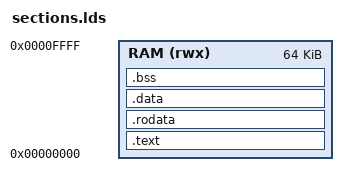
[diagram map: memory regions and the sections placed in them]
/*
 * Linker script for PicoRV32 64KB bare-metal environment
 */
OUTPUT_FORMAT("elf32-littleriscv", "elf32-littleriscv", "elf32-littleriscv")
OUTPUT_ARCH(riscv)
ENTRY(_start)

MEMORY
{
    RAM (rwx) : ORIGIN = 0x00000000, LENGTH = 64K
}

SECTIONS
{
    .text :
    {
        . = ALIGN(4);
        *(.text.entry)
        *(.text)
        *(.text.*)
        . = ALIGN(4);
        _etext = .;
    } > RAM

    .rodata :
    {
        . = ALIGN(4);
        *(.rodata)
        *(.rodata.*)
        *(.srodata)
        *(.srodata.*)
        . = ALIGN(4);
    } > RAM

    .data :
    {
        . = ALIGN(4);
        _sdata = .;
        *(.data)
        *(.data.*)
        *(.sdata)
        *(.sdata.*)
        . = ALIGN(4);
        _edata = .;
    } > RAM

    .bss :
    {
        . = ALIGN(4);
        _sbss = .;
        *(.bss)
        *(.bss.*)
        *(.sbss)
        *(.sbss.*)
        *(COMMON)
        . = ALIGN(4);
        _ebss = .;
    } > RAM

    /* Set stack at the very end of 64 KB RAM */
    _stack_top = ORIGIN(RAM) + LENGTH(RAM);
}
